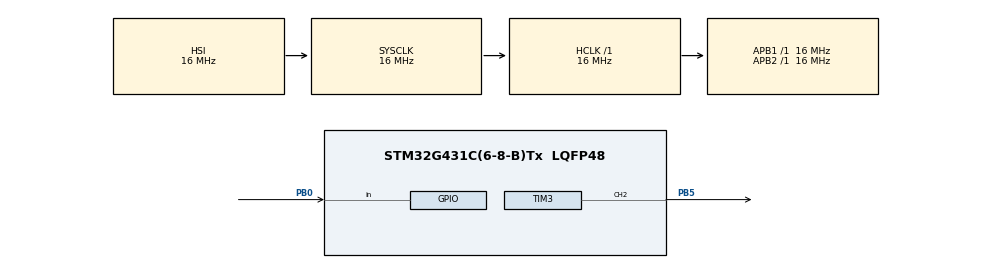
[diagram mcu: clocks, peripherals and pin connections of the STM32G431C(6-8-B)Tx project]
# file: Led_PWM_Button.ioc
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Mcu.Family=STM32G4
Mcu.Name=STM32G431C(6-8-B)Tx
Mcu.Package=LQFP48
NVIC.PriorityGroup=NVIC_PRIORITYGROUP_4
PB0.Signal=GPIO_Input
PB5.Signal=S_TIM3_CH2
ProjectManager.HeapSize=0x200
ProjectManager.StackSize=0x400
ProjectManager.TargetToolchain=STM32CubeIDE
RCC.AHBFreq_Value=16000000
RCC.APB1Freq_Value=16000000
RCC.APB1TimFreq_Value=16000000
RCC.APB2Freq_Value=16000000
RCC.APB2TimFreq_Value=16000000
RCC.CortexFreq_Value=16000000
RCC.EXTERNAL_CLOCK_VALUE=12288000
RCC.HCLKFreq_Value=16000000
RCC.HSE_VALUE=8000000
RCC.HSI48_VALUE=48000000
RCC.HSI_VALUE=16000000
RCC.LSE_VALUE=32768
RCC.SYSCLKFreq_VALUE=16000000
RCC.USBFreq_Value=64000000
RCC.VCOOutputFreq_Value=128000000
SH.S_TIM3_CH2.0=TIM3_CH2,PWM Generation2 CH2
TIM3.AutoReloadPreload=TIM_AUTORELOAD_PRELOAD_ENABLE
TIM3.Channel-PWM\ Generation2\ CH2=TIM_CHANNEL_2
TIM3.PeriodNoDither=49
TIM3.Prescaler=15
TIM3.PulseNoDither_2=0
VP_SYS_VS_DBSignals.Mode=DisableDeadBatterySignals
VP_TIM3_VS_ClockSourceINT.Mode=Internal
board=custom

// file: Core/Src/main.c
/* USER CODE BEGIN Header */
/**
  ******************************************************************************
  * @file           : main.c
  * @brief          : Main program body
  ******************************************************************************
  * @attention
  *
  * Copyright (c) 2025 STMicroelectronics.
  * All rights reserved.
  *
  * This software is licensed under terms that can be found in the LICENSE file
  * in the root directory of this software component.
  * If no LICENSE file comes with this software, it is provided AS-IS.
  *
  ******************************************************************************
  */
/* USER CODE END Header */
#include "main.h"

TIM_HandleTypeDef htim3;

void SystemClock_Config(void);
static void MX_GPIO_Init(void);
static void MX_TIM3_Init(void);

/* USER CODE BEGIN 0 */
void pulse_led();
/* USER CODE END 0 */

int main(void)
{

  /* MCU Configuration--------------------------------------------------------*/

  /* Reset of all peripherals, Initializes the Flash interface and the Systick. */
  HAL_Init();

  /* Configure the system clock */
  SystemClock_Config();

  /* Initialize all configured peripherals */
  MX_GPIO_Init();
  MX_TIM3_Init();
  /* USER CODE BEGIN 2 */
  // start timer
  HAL_TIM_PWM_Start(&htim3, TIM_CHANNEL_2);
  /* USER CODE END 2 */

  /* Infinite loop */
  while (1)
  {

    /* USER CODE BEGIN 3 */
	  GPIO_PinState button_value = HAL_GPIO_ReadPin(GPIOB, GPIO_PIN_0);
	  if (button_value == GPIO_PIN_RESET) {
		  pulse_led();
	  }
	  __HAL_TIM_SET_COMPARE(&htim3, TIM_CHANNEL_2, 0);

  }
  /* USER CODE END 3 */
}

void SystemClock_Config(void)
{
  RCC_OscInitTypeDef RCC_OscInitStruct = {0};
  RCC_ClkInitTypeDef RCC_ClkInitStruct = {0};

  /** Configure the main internal regulator output voltage
  */
  HAL_PWREx_ControlVoltageScaling(PWR_REGULATOR_VOLTAGE_SCALE1);

  /** Initializes the RCC Oscillators according to the specified parameters
  * in the RCC_OscInitTypeDef structure.
  */
  RCC_OscInitStruct.OscillatorType = RCC_OSCILLATORTYPE_HSI;
  RCC_OscInitStruct.HSIState = RCC_HSI_ON;
  RCC_OscInitStruct.HSICalibrationValue = RCC_HSICALIBRATION_DEFAULT;
  RCC_OscInitStruct.PLL.PLLState = RCC_PLL_NONE;
  if (HAL_RCC_OscConfig(&RCC_OscInitStruct) != HAL_OK)
  {
    Error_Handler();
  }

  /** Initializes the CPU, AHB and APB buses clocks
  */
  RCC_ClkInitStruct.ClockType = RCC_CLOCKTYPE_HCLK|RCC_CLOCKTYPE_SYSCLK
                              |RCC_CLOCKTYPE_PCLK1|RCC_CLOCKTYPE_PCLK2;
  RCC_ClkInitStruct.SYSCLKSource = RCC_SYSCLKSOURCE_HSI;
  RCC_ClkInitStruct.AHBCLKDivider = RCC_SYSCLK_DIV1;
  RCC_ClkInitStruct.APB1CLKDivider = RCC_HCLK_DIV1;
  RCC_ClkInitStruct.APB2CLKDivider = RCC_HCLK_DIV1;

  if (HAL_RCC_ClockConfig(&RCC_ClkInitStruct, FLASH_LATENCY_0) != HAL_OK)
  {
    Error_Handler();
  }
}

static void MX_TIM3_Init(void)
{

  TIM_ClockConfigTypeDef sClockSourceConfig = {0};
  TIM_MasterConfigTypeDef sMasterConfig = {0};
  TIM_OC_InitTypeDef sConfigOC = {0};

  htim3.Instance = TIM3;
  htim3.Init.Prescaler = 15;
  htim3.Init.CounterMode = TIM_COUNTERMODE_UP;
  htim3.Init.Period = 49;
  htim3.Init.ClockDivision = TIM_CLOCKDIVISION_DIV1;
  htim3.Init.AutoReloadPreload = TIM_AUTORELOAD_PRELOAD_ENABLE;
  if (HAL_TIM_Base_Init(&htim3) != HAL_OK)
  {
    Error_Handler();
  }
  sClockSourceConfig.ClockSource = TIM_CLOCKSOURCE_INTERNAL;
  if (HAL_TIM_ConfigClockSource(&htim3, &sClockSourceConfig) != HAL_OK)
  {
    Error_Handler();
  }
  if (HAL_TIM_PWM_Init(&htim3) != HAL_OK)
  {
    Error_Handler();
  }
  sMasterConfig.MasterOutputTrigger = TIM_TRGO_RESET;
  sMasterConfig.MasterSlaveMode = TIM_MASTERSLAVEMODE_DISABLE;
  if (HAL_TIMEx_MasterConfigSynchronization(&htim3, &sMasterConfig) != HAL_OK)
  {
    Error_Handler();
  }
  sConfigOC.OCMode = TIM_OCMODE_PWM1;
  sConfigOC.Pulse = 0;
  sConfigOC.OCPolarity = TIM_OCPOLARITY_HIGH;
  sConfigOC.OCFastMode = TIM_OCFAST_DISABLE;
  if (HAL_TIM_PWM_ConfigChannel(&htim3, &sConfigOC, TIM_CHANNEL_2) != HAL_OK)
  {
    Error_Handler();
  }
  HAL_TIM_MspPostInit(&htim3);

}

static void MX_GPIO_Init(void)
{
  GPIO_InitTypeDef GPIO_InitStruct = {0};

  /* GPIO Ports Clock Enable */
  __HAL_RCC_GPIOB_CLK_ENABLE();

  /*Configure GPIO pin : PB0 */
  GPIO_InitStruct.Pin = GPIO_PIN_0;
  GPIO_InitStruct.Mode = GPIO_MODE_INPUT;
  GPIO_InitStruct.Pull = GPIO_NOPULL;
  HAL_GPIO_Init(GPIOB, &GPIO_InitStruct);

}

/* USER CODE BEGIN 4 */
void pulse_led() {
	for (int i = 0; i < 49; i++) {
	  __HAL_TIM_SET_COMPARE(&htim3, TIM_CHANNEL_2, i);
	  HAL_Delay(10);
	}
	HAL_Delay(200);
	for (int i = 49; i > 0; i--) {
		  __HAL_TIM_SET_COMPARE(&htim3, TIM_CHANNEL_2, i);
		  HAL_Delay(10);
	}
}
/* USER CODE END 4 */

void Error_Handler(void)
{
  __disable_irq();
  while (1)
  {
  }
}
